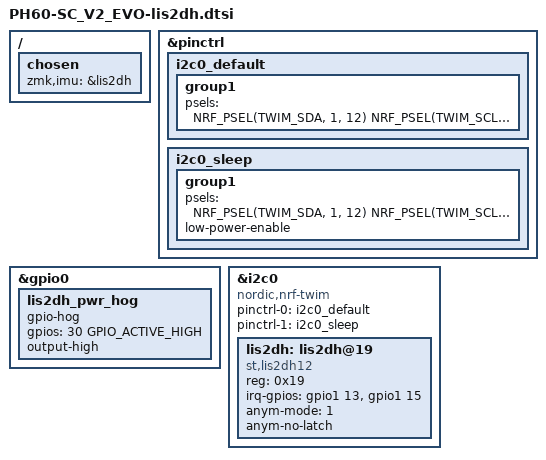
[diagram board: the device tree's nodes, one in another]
/*
 * Copyright (c) 2025 Team PHDesign
 *
 * SPDX-License-Identifier: MIT
 */

&pinctrl {
        i2c0_default: i2c0_default {
                group1 {
                        psels = <NRF_PSEL(TWIM_SDA, 1, 12) NRF_PSEL(TWIM_SCL, 1, 11)>;
                };
        };

        i2c0_sleep: i2c0_sleep {
                group1 {
                        psels = <NRF_PSEL(TWIM_SDA, 1, 12) NRF_PSEL(TWIM_SCL, 1, 11)>;
                        low-power-enable;
                };
        };
};

&gpio0 {
        // IMU VDD is fed from P0.30 so the sensor can be power-cycled by firmware
        lis2dh_pwr_hog: lis2dh_pwr_hog {
                gpio-hog;
                gpios = <30 GPIO_ACTIVE_HIGH>;
                output-high;
        };
};


/ {
        chosen {
                zmk,imu = &lis2dh;
        };
};

&i2c0 {
        compatible = "nordic,nrf-twim";
        status = "okay";

        pinctrl-0 = <&i2c0_default>;
        pinctrl-1 = <&i2c0_sleep>;
        pinctrl-names = "default", "sleep";

        lis2dh: lis2dh@19 {
                compatible = "st,lis2dh12", "st,lis2dh";
                reg = <0x19>;
                irq-gpios = <&gpio1 13 GPIO_ACTIVE_HIGH>, <&gpio1 15 GPIO_ACTIVE_HIGH>;
                // 6D movement: gravity-zone based, immune to HPF reference offset
                anym-mode = <1>;
                // 6D movement pulses the line for one ODR; latching it makes the
                // level IRQ re-fire forever after every INT2_SRC read
                anym-no-latch;
        };
};
